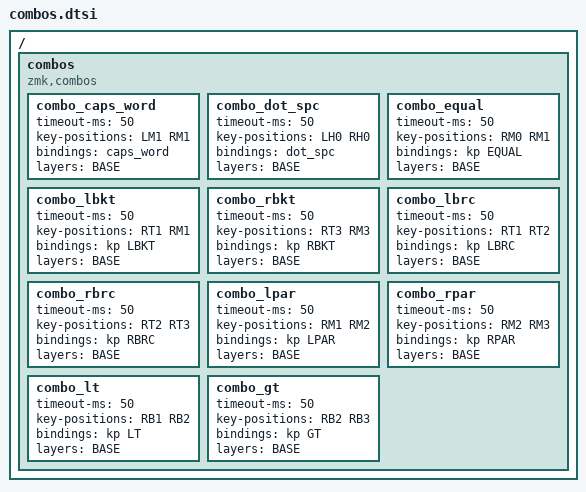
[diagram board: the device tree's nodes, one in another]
/ {
  combos {
    compatible = "zmk,combos";

    combo_caps_word {
      timeout-ms = <50>;
      key-positions = <LM1 RM1>;
      bindings = <&caps_word>;
      layers = <BASE>;
    };

    // combo_reset {
    //   timeout-ms = <50>;
    //   key-positions = <LT0 RT0>;
    //   bindings = <&sys_reset>;
    //   layers = <BASE>;
    // };
    //
    // combo_boot {
    //   timeout-ms = <50>;
    //   key-positions = <LB0 RB0>;
    //   bindings = <&bootloader>;
    //   layers = <BASE>;
    // };

    combo_dot_spc {
      timeout-ms = <50>;
      key-positions = <LH0 RH0>;
      bindings = <&dot_spc>;
      layers = <BASE>;
    };

    combo_equal {
      timeout-ms = <50>;
      key-positions = <RM0 RM1>;
      bindings = <&kp EQUAL>;
      layers = <BASE>;
    };

    // [
    combo_lbkt {
      timeout-ms = <50>;
      key-positions = <RT1 RM1>;
      bindings = <&kp LBKT>;
      layers = <BASE>;
    };

    // ]
    combo_rbkt {
      timeout-ms = <50>;
      key-positions = <RT3 RM3>;
      bindings = <&kp RBKT>;
      layers = <BASE>;
    };

    // {
    combo_lbrc {
      timeout-ms = <50>;
      key-positions = <RT1 RT2>;
      bindings = <&kp LBRC>;
      layers = <BASE>;
    };

    // }
    combo_rbrc {
      timeout-ms = <50>;
      key-positions = <RT2 RT3>;
      bindings = <&kp RBRC>;
      layers = <BASE>;
    };

    // (
    combo_lpar {
      timeout-ms = <50>;
      key-positions = <RM1 RM2>;
      bindings = <&kp LPAR>;
      layers = <BASE>;
    };

    // )
    combo_rpar {
      timeout-ms = <50>;
      key-positions = <RM2 RM3>;
      bindings = <&kp RPAR>;
      layers = <BASE>;
    };

    // <
    combo_lt {
      timeout-ms = <50>;
      key-positions = <RB1 RB2>;
      bindings = <&kp LT>;
      layers = <BASE>;
    };

    // >
    combo_gt {
      timeout-ms = <50>;
      key-positions = <RB2 RB3>;
      bindings = <&kp GT>;
      layers = <BASE>;
    };

  };
};
